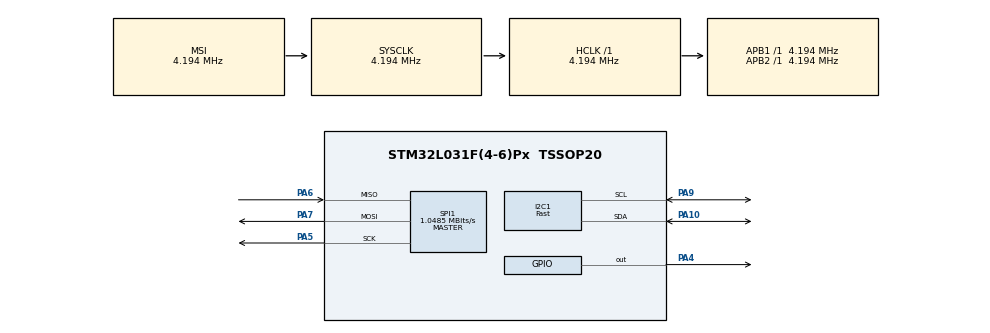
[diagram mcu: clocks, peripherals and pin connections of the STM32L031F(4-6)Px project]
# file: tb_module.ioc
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Dma.I2C1_TX.2.Direction=DMA_MEMORY_TO_PERIPH
Dma.I2C1_TX.2.Instance=DMA1_Channel6
Dma.I2C1_TX.2.MemDataAlignment=DMA_MDATAALIGN_BYTE
Dma.I2C1_TX.2.MemInc=DMA_MINC_ENABLE
Dma.I2C1_TX.2.Mode=DMA_NORMAL
Dma.I2C1_TX.2.PeriphDataAlignment=DMA_PDATAALIGN_BYTE
Dma.I2C1_TX.2.PeriphInc=DMA_PINC_DISABLE
Dma.I2C1_TX.2.Priority=DMA_PRIORITY_LOW
Dma.Request0=SPI1_TX
Dma.Request1=SPI1_RX
Dma.Request2=I2C1_TX
Dma.SPI1_RX.1.Direction=DMA_PERIPH_TO_MEMORY
Dma.SPI1_RX.1.Instance=DMA1_Channel2
Dma.SPI1_RX.1.MemDataAlignment=DMA_MDATAALIGN_BYTE
Dma.SPI1_RX.1.MemInc=DMA_MINC_ENABLE
Dma.SPI1_RX.1.Mode=DMA_NORMAL
Dma.SPI1_RX.1.PeriphDataAlignment=DMA_PDATAALIGN_BYTE
Dma.SPI1_RX.1.PeriphInc=DMA_PINC_DISABLE
Dma.SPI1_RX.1.Priority=DMA_PRIORITY_MEDIUM
Dma.SPI1_TX.0.Direction=DMA_MEMORY_TO_PERIPH
Dma.SPI1_TX.0.Instance=DMA1_Channel3
Dma.SPI1_TX.0.MemDataAlignment=DMA_MDATAALIGN_BYTE
Dma.SPI1_TX.0.MemInc=DMA_MINC_ENABLE
Dma.SPI1_TX.0.Mode=DMA_NORMAL
Dma.SPI1_TX.0.PeriphDataAlignment=DMA_PDATAALIGN_BYTE
Dma.SPI1_TX.0.PeriphInc=DMA_PINC_DISABLE
Dma.SPI1_TX.0.Priority=DMA_PRIORITY_MEDIUM
I2C1.I2C_Speed_Mode=I2C_Fast
I2C1.OwnAddress=0x1E
I2C1.Speed=400
I2C1.Timing=0x00000004
Mcu.Family=STM32L0
Mcu.Name=STM32L031F(4-6)Px
Mcu.Package=TSSOP20
NVIC.DMA1_Channel2_3_IRQn=true\:0\:0\:false\:false\:true\:false\:true
NVIC.DMA1_Channel4_5_6_7_IRQn=true\:0\:0\:false\:false\:true\:false\:true
NVIC.I2C1_IRQn=true\:0\:0\:false\:false\:true\:true\:true
PA10.Mode=I2C
PA10.Signal=I2C1_SDA
PA13.Mode=Serial_Wire
PA13.Signal=SYS_SWDIO
PA14.Mode=Serial_Wire
PA14.Signal=SYS_SWCLK
PA4.PinState=GPIO_PIN_SET
PA4.Signal=GPIO_Output
PA5.Mode=Full_Duplex_Master
PA5.Signal=SPI1_SCK
PA6.Mode=Full_Duplex_Master
PA6.Signal=SPI1_MISO
PA7.Mode=Full_Duplex_Master
PA7.Signal=SPI1_MOSI
PA9.Mode=I2C
PA9.Signal=I2C1_SCL
ProjectManager.HeapSize=0x200
ProjectManager.StackSize=0x400
ProjectManager.TargetToolchain=Makefile
RCC.AHBFreq_Value=4194000
RCC.APB1Freq_Value=4194000
RCC.APB1TimFreq_Value=4194000
RCC.APB2Freq_Value=4194000
RCC.APB2TimFreq_Value=4194000
RCC.HCLKFreq_Value=4194000
RCC.HSE_VALUE=8000000
RCC.HSI16_VALUE=16000000
RCC.HSI_VALUE=16000000
RCC.LSE_VALUE=32768
RCC.MSIClockRange=RCC_MSIRANGE_6
RCC.MSI_VALUE=4194000
RCC.SYSCLKFreq_VALUE=4194000
RCC.VCOOutputFreq_Value=48000000
SPI1.BaudRatePrescaler=SPI_BAUDRATEPRESCALER_4
SPI1.CLKPhase=SPI_PHASE_2EDGE
SPI1.CLKPolarity=SPI_POLARITY_HIGH
SPI1.CalculateBaudRate=1.0485 MBits/s
SPI1.Direction=SPI_DIRECTION_2LINES
SPI1.Mode=SPI_MODE_MASTER
SPI1.VirtualType=VM_MASTER
board=custom

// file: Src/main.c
/* USER CODE BEGIN Header */
/**
  ******************************************************************************
  * @file           : main.c
  * @brief          : Main program body
  ******************************************************************************
  * @attention
  *
  * <h2><center>&copy; Copyright (c) 2019 STMicroelectronics.
  * All rights reserved.</center></h2>
  *
  * This software component is licensed by ST under BSD 3-Clause license,
  * the "License"; You may not use this file except in compliance with the
  * License. You may obtain a copy of the License at:
  *                        opensource.org/licenses/BSD-3-Clause
  *
  ******************************************************************************
  */
/* USER CODE END Header */

#include "main.h"

/* USER CODE BEGIN Includes */
#include "user.h"
/* USER CODE END Includes */

I2C_HandleTypeDef hi2c1;
DMA_HandleTypeDef hdma_i2c1_tx;

SPI_HandleTypeDef hspi1;
DMA_HandleTypeDef hdma_spi1_tx;
DMA_HandleTypeDef hdma_spi1_rx;

void SystemClock_Config(void);
static void MX_GPIO_Init(void);
static void MX_I2C1_Init(void);
static void MX_SPI1_Init(void);
static void MX_DMA_Init(void);

int main(void)
{

  /* MCU Configuration--------------------------------------------------------*/

  /* Reset of all peripherals, Initializes the Flash interface and the Systick. */
  HAL_Init();

  /* Configure the system clock */
  SystemClock_Config();

  /* USER CODE BEGIN SysInit */
  MX_DMA_Init();
  /* USER CODE END SysInit */

  /* Initialize all configured peripherals */
  MX_GPIO_Init();
  MX_I2C1_Init();
  MX_SPI1_Init();
  /* USER CODE BEGIN 2 */
  // HAL_I2C_EnableListen_IT(&hi2c1);
  user_init();
  user_main();
  /* USER CODE END 2 */

  /* Infinite loop */
  while (1)
  {

  }
}

void SystemClock_Config(void)
{
  RCC_OscInitTypeDef RCC_OscInitStruct = {0};
  RCC_ClkInitTypeDef RCC_ClkInitStruct = {0};
  RCC_PeriphCLKInitTypeDef PeriphClkInit = {0};

  /** Configure the main internal regulator output voltage
  */
  __HAL_PWR_VOLTAGESCALING_CONFIG(PWR_REGULATOR_VOLTAGE_SCALE1);
  /** Initializes the CPU, AHB and APB busses clocks
  */
  RCC_OscInitStruct.OscillatorType = RCC_OSCILLATORTYPE_MSI;
  RCC_OscInitStruct.MSIState = RCC_MSI_ON;
  RCC_OscInitStruct.MSICalibrationValue = 0;
  RCC_OscInitStruct.MSIClockRange = RCC_MSIRANGE_6;
  RCC_OscInitStruct.PLL.PLLState = RCC_PLL_NONE;
  if (HAL_RCC_OscConfig(&RCC_OscInitStruct) != HAL_OK)
  {
    Error_Handler();
  }
  /** Initializes the CPU, AHB and APB busses clocks
  */
  RCC_ClkInitStruct.ClockType = RCC_CLOCKTYPE_HCLK|RCC_CLOCKTYPE_SYSCLK
                              |RCC_CLOCKTYPE_PCLK1|RCC_CLOCKTYPE_PCLK2;
  RCC_ClkInitStruct.SYSCLKSource = RCC_SYSCLKSOURCE_MSI;
  RCC_ClkInitStruct.AHBCLKDivider = RCC_SYSCLK_DIV1;
  RCC_ClkInitStruct.APB1CLKDivider = RCC_HCLK_DIV1;
  RCC_ClkInitStruct.APB2CLKDivider = RCC_HCLK_DIV1;

  if (HAL_RCC_ClockConfig(&RCC_ClkInitStruct, FLASH_LATENCY_0) != HAL_OK)
  {
    Error_Handler();
  }
  PeriphClkInit.PeriphClockSelection = RCC_PERIPHCLK_I2C1;
  PeriphClkInit.I2c1ClockSelection = RCC_I2C1CLKSOURCE_PCLK1;
  if (HAL_RCCEx_PeriphCLKConfig(&PeriphClkInit) != HAL_OK)
  {
    Error_Handler();
  }
}

static void MX_I2C1_Init(void)
{

  hi2c1.Instance = I2C1;
  hi2c1.Init.Timing = 0x00000004;
  hi2c1.Init.OwnAddress1 = 60;
  hi2c1.Init.AddressingMode = I2C_ADDRESSINGMODE_7BIT;
  hi2c1.Init.DualAddressMode = I2C_DUALADDRESS_DISABLE;
  hi2c1.Init.OwnAddress2 = 0;
  hi2c1.Init.OwnAddress2Masks = I2C_OA2_NOMASK;
  hi2c1.Init.GeneralCallMode = I2C_GENERALCALL_DISABLE;
  hi2c1.Init.NoStretchMode = I2C_NOSTRETCH_DISABLE;
  if (HAL_I2C_Init(&hi2c1) != HAL_OK)
  {
    Error_Handler();
  }
  /** Configure Analogue filter
  */
  if (HAL_I2CEx_ConfigAnalogFilter(&hi2c1, I2C_ANALOGFILTER_ENABLE) != HAL_OK)
  {
    Error_Handler();
  }
  /** Configure Digital filter
  */
  if (HAL_I2CEx_ConfigDigitalFilter(&hi2c1, 0) != HAL_OK)
  {
    Error_Handler();
  }

}

static void MX_SPI1_Init(void)
{

  /* SPI1 parameter configuration*/
  hspi1.Instance = SPI1;
  hspi1.Init.Mode = SPI_MODE_MASTER;
  hspi1.Init.Direction = SPI_DIRECTION_2LINES;
  hspi1.Init.DataSize = SPI_DATASIZE_8BIT;
  hspi1.Init.CLKPolarity = SPI_POLARITY_HIGH;
  hspi1.Init.CLKPhase = SPI_PHASE_2EDGE;
  hspi1.Init.NSS = SPI_NSS_SOFT;
  hspi1.Init.BaudRatePrescaler = SPI_BAUDRATEPRESCALER_4;
  hspi1.Init.FirstBit = SPI_FIRSTBIT_MSB;
  hspi1.Init.TIMode = SPI_TIMODE_DISABLE;
  hspi1.Init.CRCCalculation = SPI_CRCCALCULATION_DISABLE;
  hspi1.Init.CRCPolynomial = 7;
  if (HAL_SPI_Init(&hspi1) != HAL_OK)
  {
    Error_Handler();
  }

}

static void MX_DMA_Init(void)
{

  /* DMA controller clock enable */
  __HAL_RCC_DMA1_CLK_ENABLE();

  /* DMA interrupt init */
  /* DMA1_Channel2_3_IRQn interrupt configuration */
  HAL_NVIC_SetPriority(DMA1_Channel2_3_IRQn, 0, 0);
  HAL_NVIC_EnableIRQ(DMA1_Channel2_3_IRQn);
  /* DMA1_Channel4_5_6_7_IRQn interrupt configuration */
  HAL_NVIC_SetPriority(DMA1_Channel4_5_6_7_IRQn, 0, 0);
  HAL_NVIC_EnableIRQ(DMA1_Channel4_5_6_7_IRQn);

}

static void MX_GPIO_Init(void)
{
  GPIO_InitTypeDef GPIO_InitStruct = {0};

  /* GPIO Ports Clock Enable */
  __HAL_RCC_GPIOA_CLK_ENABLE();

  /*Configure GPIO pin Output Level */
  HAL_GPIO_WritePin(GPIOA, GPIO_PIN_4, GPIO_PIN_SET);

  /*Configure GPIO pin : PA4 */
  GPIO_InitStruct.Pin = GPIO_PIN_4;
  GPIO_InitStruct.Mode = GPIO_MODE_OUTPUT_PP;
  GPIO_InitStruct.Pull = GPIO_NOPULL;
  GPIO_InitStruct.Speed = GPIO_SPEED_FREQ_LOW;
  HAL_GPIO_Init(GPIOA, &GPIO_InitStruct);

}

void Error_Handler(void)
{
}

/************************ (C) COPYRIGHT STMicroelectronics *****END OF FILE****/
